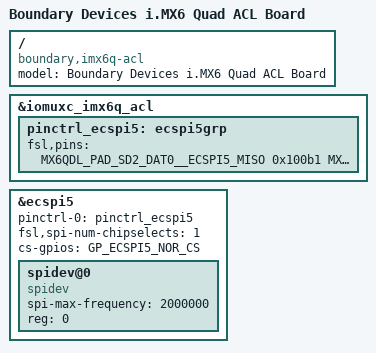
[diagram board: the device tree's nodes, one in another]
/*
 * Copyright 2016 Boundary Devices, Inc.
 *
 * The code contained herein is licensed under the GNU General Public
 * License. You may obtain a copy of the GNU General Public License
 * Version 2 or later at the following locations:
 *
 * http://www.opensource.org/licenses/gpl-license.html
 * http://www.gnu.org/copyleft/gpl.html
 */

/dts-v1/;

#include <dt-bindings/interrupt-controller/irq.h>
#include "imx6q.dtsi"
#include "imx6qdl-acl.dtsi"

/ {
	model = "Boundary Devices i.MX6 Quad ACL Board";
	compatible = "boundary,imx6q-acl", "fsl,imx6q";
};

&iomuxc_imx6q_acl {
	pinctrl_ecspi5: ecspi5grp {
		fsl,pins = <
			MX6QDL_PAD_SD2_DAT0__ECSPI5_MISO	0x100b1
			MX6QDL_PAD_SD2_CMD__ECSPI5_MOSI		0x100b1
			MX6QDL_PAD_SD2_CLK__ECSPI5_SCLK		0x000b1
#define GP_ECSPI5_NOR_CS	<&gpio1 14 GPIO_ACTIVE_LOW>
			MX6QDL_PAD_SD2_DAT1__GPIO1_IO14		0x0b0b1
		>;
	};
};

&ecspi5 {
	pinctrl-names = "default";
	pinctrl-0 = <&pinctrl_ecspi5>;
	fsl,spi-num-chipselects = <1>;
	cs-gpios = GP_ECSPI5_NOR_CS;
	status = "okay";

	spidev@0 {
		compatible = "spidev";
		spi-max-frequency = <2000000>;
		reg = <0>;
	};
};
